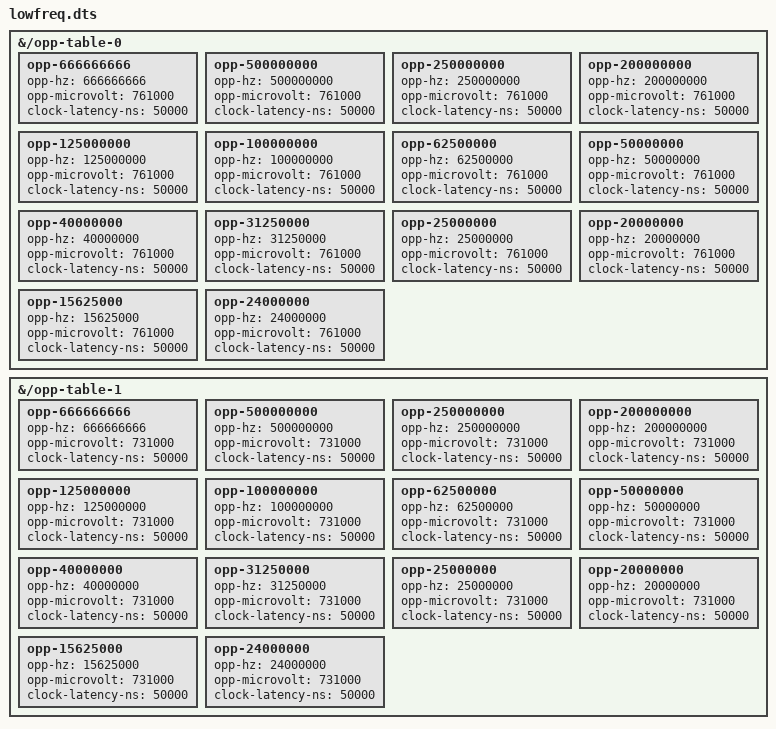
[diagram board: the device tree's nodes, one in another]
/dts-v1/;
/plugin/;

/*
 * Adds CPU OPP entries below 1 GHz to the ODROID-N2(+) device tree.
 *
 * The stock opp-table-0 (Cortex-A53 "little", policy0) and opp-table-1
 * (Cortex-A73 "big", policy2) start at 1.0 GHz, so cpufreq cannot select
 * anything slower even though the meson clock tree can. cpu_clk_dyn0_sel muxes
 * xtal, fclk_div2 and fclk_div3 through a 6-bit divider, so every rate below is
 * parent/div exactly:
 *
 *   666666666   = fclk_div3 / 1
 *   500000000   = fclk_div2 / 2
 *   250000000   = fclk_div2 / 4
 *   200000000   = fclk_div2 / 5
 *   125000000   = fclk_div2 / 8
 *   100000000   = fclk_div2 / 10
 *   62500000    = fclk_div2 / 16
 *   50000000    = fclk_div2 / 20
 *   40000000    = fclk_div2 / 25
 *   31250000    = fclk_div2 / 32
 *   25000000    = fclk_div2 / 40
 *   20000000    = fclk_div2 / 50
 *   15625000    = fclk_div2 / 64
 *   24000000    = xtal / 1
 *
 * 24 MHz is the hard floor: xtal is the lowest mux parent, and it is also the
 * driver's own parking clock, so the core demonstrably runs there. Rates below
 * it are not reachable through this mux.
 *
 * The voltages are the stock 1.0 GHz values: this overlay only unlocks the
 * frequency, undervolting is a separate experiment. They also sit well above
 * the regulator floor (680 mV).
 *
 * These points are NOT reachable at boot: cpufreq.default_governor=performance
 * keeps early boot at maximum frequency and cpu-freq-guard.sh pins
 * scaling_min_freq to 1.0 GHz, so a bad low point can only be hit by an
 * explicit runtime probe - a reset then restores the floor instead of looping.
 */

/ {
	fragment@0 {
		target-path = "/opp-table-0";
		__overlay__ {
			opp-666666666 {
				opp-hz = /bits/ 64 <666666666>;
				opp-microvolt = <761000>;
				clock-latency-ns = <50000>;
			};
			opp-500000000 {
				opp-hz = /bits/ 64 <500000000>;
				opp-microvolt = <761000>;
				clock-latency-ns = <50000>;
			};
			opp-250000000 {
				opp-hz = /bits/ 64 <250000000>;
				opp-microvolt = <761000>;
				clock-latency-ns = <50000>;
			};
			opp-200000000 {
				opp-hz = /bits/ 64 <200000000>;
				opp-microvolt = <761000>;
				clock-latency-ns = <50000>;
			};
			opp-125000000 {
				opp-hz = /bits/ 64 <125000000>;
				opp-microvolt = <761000>;
				clock-latency-ns = <50000>;
			};
			opp-100000000 {
				opp-hz = /bits/ 64 <100000000>;
				opp-microvolt = <761000>;
				clock-latency-ns = <50000>;
			};
			opp-62500000 {
				opp-hz = /bits/ 64 <62500000>;
				opp-microvolt = <761000>;
				clock-latency-ns = <50000>;
			};
			opp-50000000 {
				opp-hz = /bits/ 64 <50000000>;
				opp-microvolt = <761000>;
				clock-latency-ns = <50000>;
			};
			opp-40000000 {
				opp-hz = /bits/ 64 <40000000>;
				opp-microvolt = <761000>;
				clock-latency-ns = <50000>;
			};
			opp-31250000 {
				opp-hz = /bits/ 64 <31250000>;
				opp-microvolt = <761000>;
				clock-latency-ns = <50000>;
			};
			opp-25000000 {
				opp-hz = /bits/ 64 <25000000>;
				opp-microvolt = <761000>;
				clock-latency-ns = <50000>;
			};
			opp-20000000 {
				opp-hz = /bits/ 64 <20000000>;
				opp-microvolt = <761000>;
				clock-latency-ns = <50000>;
			};
			opp-15625000 {
				opp-hz = /bits/ 64 <15625000>;
				opp-microvolt = <761000>;
				clock-latency-ns = <50000>;
			};
			opp-24000000 {
				opp-hz = /bits/ 64 <24000000>;
				opp-microvolt = <761000>;
				clock-latency-ns = <50000>;
			};
		};
	};
};

/ {
	fragment@1 {
		target-path = "/opp-table-1";
		__overlay__ {
			opp-666666666 {
				opp-hz = /bits/ 64 <666666666>;
				opp-microvolt = <731000>;
				clock-latency-ns = <50000>;
			};
			opp-500000000 {
				opp-hz = /bits/ 64 <500000000>;
				opp-microvolt = <731000>;
				clock-latency-ns = <50000>;
			};
			opp-250000000 {
				opp-hz = /bits/ 64 <250000000>;
				opp-microvolt = <731000>;
				clock-latency-ns = <50000>;
			};
			opp-200000000 {
				opp-hz = /bits/ 64 <200000000>;
				opp-microvolt = <731000>;
				clock-latency-ns = <50000>;
			};
			opp-125000000 {
				opp-hz = /bits/ 64 <125000000>;
				opp-microvolt = <731000>;
				clock-latency-ns = <50000>;
			};
			opp-100000000 {
				opp-hz = /bits/ 64 <100000000>;
				opp-microvolt = <731000>;
				clock-latency-ns = <50000>;
			};
			opp-62500000 {
				opp-hz = /bits/ 64 <62500000>;
				opp-microvolt = <731000>;
				clock-latency-ns = <50000>;
			};
			opp-50000000 {
				opp-hz = /bits/ 64 <50000000>;
				opp-microvolt = <731000>;
				clock-latency-ns = <50000>;
			};
			opp-40000000 {
				opp-hz = /bits/ 64 <40000000>;
				opp-microvolt = <731000>;
				clock-latency-ns = <50000>;
			};
			opp-31250000 {
				opp-hz = /bits/ 64 <31250000>;
				opp-microvolt = <731000>;
				clock-latency-ns = <50000>;
			};
			opp-25000000 {
				opp-hz = /bits/ 64 <25000000>;
				opp-microvolt = <731000>;
				clock-latency-ns = <50000>;
			};
			opp-20000000 {
				opp-hz = /bits/ 64 <20000000>;
				opp-microvolt = <731000>;
				clock-latency-ns = <50000>;
			};
			opp-15625000 {
				opp-hz = /bits/ 64 <15625000>;
				opp-microvolt = <731000>;
				clock-latency-ns = <50000>;
			};
			opp-24000000 {
				opp-hz = /bits/ 64 <24000000>;
				opp-microvolt = <731000>;
				clock-latency-ns = <50000>;
			};
		};
	};
};
